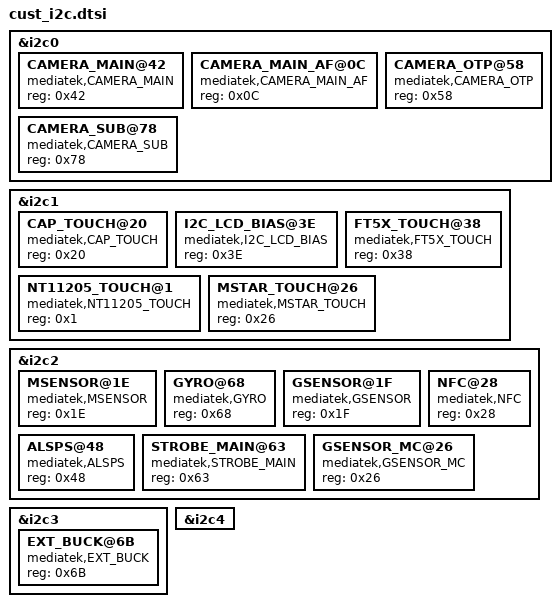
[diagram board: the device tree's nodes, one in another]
/*
 * Generated by MTK SP DrvGen Version 03.13.6 for MT6753. Copyright MediaTek Inc. (C) 2013.
 * Fri Jan 06 10:43:18 2017
 * Do Not Modify the File.
 */

/*************************
 * I2C DTSI File
*************************/

&i2c0 {
	CAMERA_MAIN@42 {
		compatible = "mediatek,CAMERA_MAIN";
		reg = <0x42>;
	};

	CAMERA_MAIN_AF@0C {
		compatible = "mediatek,CAMERA_MAIN_AF";
		reg = <0x0C>;
	};

	CAMERA_SUB@78 {
		compatible = "mediatek,CAMERA_SUB";
		reg = <0x78>;
	};

	CAMERA_OTP@58 {
		compatible = "mediatek,CAMERA_OTP";
		reg = <0x58>;
	};

};

&i2c1 {
	CAP_TOUCH@20 {
		compatible = "mediatek,CAP_TOUCH";
		reg = <0x20>;
	};

	I2C_LCD_BIAS@3E {
		compatible = "mediatek,I2C_LCD_BIAS";
		reg = <0x3E>;
	};

	FT5X_TOUCH@38 {
		compatible = "mediatek,FT5X_TOUCH";
		reg = <0x38>;
	};

	NT11205_TOUCH@1 {
		compatible = "mediatek,NT11205_TOUCH";
		reg = <0x1>;
	};

	MSTAR_TOUCH@26 {
		compatible = "mediatek,MSTAR_TOUCH";
		reg = <0x26>;
	};

};

&i2c2 {
	MSENSOR@1E {
		compatible = "mediatek,MSENSOR";
		reg = <0x1E>;
	};

	GYRO@68 {
		compatible = "mediatek,GYRO";
		reg = <0x68>;
	};

	GSENSOR@1F {
		compatible = "mediatek,GSENSOR";
		reg = <0x1F>;
	};

	ALSPS@48 {
		compatible = "mediatek,ALSPS";
		reg = <0x48>;
	};

	NFC@28 {
		compatible = "mediatek,NFC";
		reg = <0x28>;
	};

	STROBE_MAIN@63 {
		compatible = "mediatek,STROBE_MAIN";
		reg = <0x63>;
	};

	GSENSOR_MC@26 {
		compatible = "mediatek,GSENSOR_MC";
		reg = <0x26>;
	};

};

&i2c3 {
	EXT_BUCK@6B {
		compatible = "mediatek,EXT_BUCK";
		reg = <0x6B>;
	};

};

&i2c4 {
};

